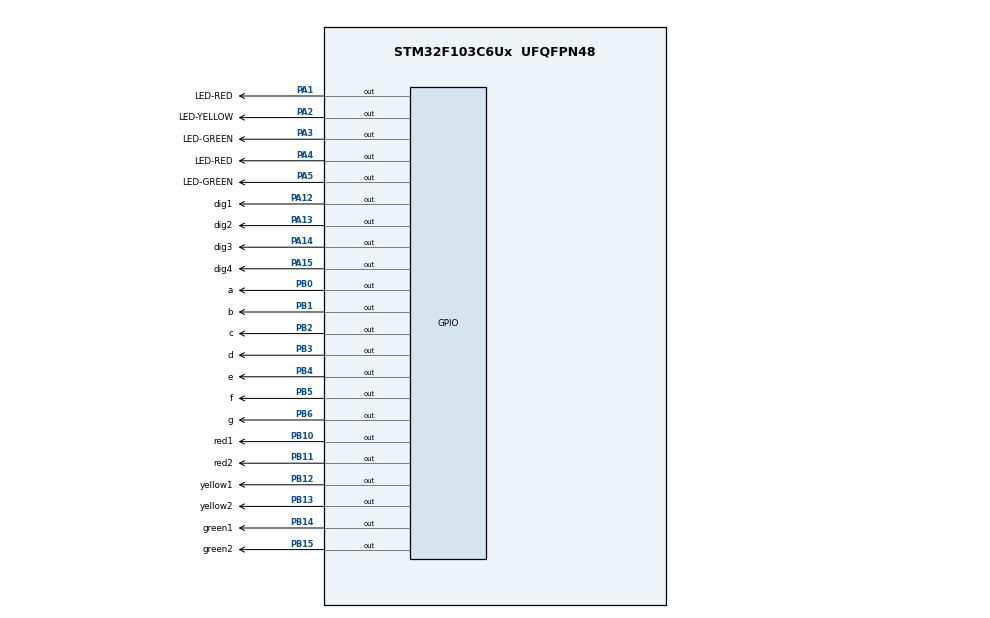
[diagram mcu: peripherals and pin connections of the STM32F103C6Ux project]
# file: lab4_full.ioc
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Mcu.Family=STM32F1
Mcu.Name=STM32F103C6Ux
Mcu.Package=UFQFPN48
NVIC.PriorityGroup=NVIC_PRIORITYGROUP_4
NVIC.TIM2_IRQn=true\:0\:0\:false\:false\:true\:true\:true
PA1.GPIO_Label=LED-RED
PA1.Signal=GPIO_Output
PA12.GPIO_Label=dig1
PA12.Signal=GPIO_Output
PA13.GPIO_Label=dig2
PA13.Signal=GPIO_Output
PA14.GPIO_Label=dig3
PA14.Signal=GPIO_Output
PA15.GPIO_Label=dig4
PA15.Signal=GPIO_Output
PA2.GPIO_Label=LED-YELLOW
PA2.Signal=GPIO_Output
PA3.GPIO_Label=LED-GREEN
PA3.Signal=GPIO_Output
PA4.GPIO_Label=LED-RED
PA4.Signal=GPIO_Output
PA5.GPIO_Label=LED-GREEN
PA5.Signal=GPIO_Output
PB0.GPIO_Label=a
PB0.Signal=GPIO_Output
PB1.GPIO_Label=b
PB1.Signal=GPIO_Output
PB10.GPIO_Label=red1
PB10.Signal=GPIO_Output
PB11.GPIO_Label=red2
PB11.Signal=GPIO_Output
PB12.GPIO_Label=yellow1
PB12.Signal=GPIO_Output
PB13.GPIO_Label=yellow2
PB13.Signal=GPIO_Output
PB14.GPIO_Label=green1
PB14.Signal=GPIO_Output
PB15.GPIO_Label=green2
PB15.Signal=GPIO_Output
PB2.GPIO_Label=c
PB2.Signal=GPIO_Output
PB3.GPIO_Label=d
PB3.Signal=GPIO_Output
PB4.GPIO_Label=e
PB4.Signal=GPIO_Output
PB5.GPIO_Label=f
PB5.Signal=GPIO_Output
PB6.GPIO_Label=g
PB6.Signal=GPIO_Output
ProjectManager.HeapSize=0x200
ProjectManager.StackSize=0x400
ProjectManager.TargetToolchain=STM32CubeIDE
RCC.APB1Freq_Value=8000000
RCC.APB2Freq_Value=8000000
TIM2.Period=9
TIM2.Prescaler=7999
VP_SYS_VS_ND.Mode=No_Debug
VP_TIM2_VS_ClockSourceINT.Mode=Internal
board=custom

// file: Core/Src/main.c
/* USER CODE BEGIN Header */
/**
  ******************************************************************************
  * @file           : main.c
  * @brief          : Main program body
  ******************************************************************************
  * @attention
  *
  * <h2><center>&copy; Copyright (c) 2024 STMicroelectronics.
  * All rights reserved.</center></h2>
  *
  * This software component is licensed by ST under BSD 3-Clause license,
  * the "License"; You may not use this file except in compliance with the
  * License. You may obtain a copy of the License at:
  * opensource.org/licenses/BSD-3-Clause
  *
  ******************************************************************************
  */
/* USER CODE END Header */
#include "main.h"

/* USER CODE BEGIN Includes */
#include "sched.h"
#include "func.h"
/* USER CODE END Includes */

TIM_HandleTypeDef htim2;

void SystemClock_Config(void);
static void MX_GPIO_Init(void);
static void MX_TIM2_Init(void);

int main(void)
{

  /* MCU Configuration--------------------------------------------------------*/

  /* Reset of all peripherals, Initializes the Flash interface and the Systick. */
  HAL_Init();

  /* Configure the system clock */
  SystemClock_Config();

  /* Initialize all configured peripherals */
  MX_GPIO_Init();
  MX_TIM2_Init();
  /* USER CODE BEGIN 2 */
  HAL_TIM_Base_Start_IT(&htim2);

  SCH_Init();

  // Yêu cầu 5 tasks: 0.5s, 1s, 1.5s, 2s, 2.5s
  // Timer tick của bạn là 10ms (từ MX_TIM2_Init, Prescaler 7999, Period 9)
  // 0.5s = 500ms  = 50 ticks
  // 1.0s = 1000ms = 100 ticks
  // 1.5s = 1500ms = 150 ticks
  // 2.0s = 2000ms = 200 ticks
  // 2.5s = 2500ms = 250 ticks

  SCH_Add_Task(turnREDLED, 10, 50, -1);     // Chạy mỗi 0.5s
  SCH_Add_Task(turnGREENLED, 10, 100, -1);  // Chạy mỗi 1.0s
  SCH_Add_Task(turnYELLOWLED, 10, 150, -1); // Chạy mỗi 1.5s
  SCH_Add_Task(turnRED, 10, 200, -1);       // Chạy mỗi 2.0s
  SCH_Add_Task(turnGreen, 10, 250, -1);     // Chạy mỗi 2.5s

  /* USER CODE END 2 */

  /* Infinite loop */
  /* USER CODE BEGIN WHILE */
  while (1)
  {
      SCH_Dispatch_Tasks(); // Yêu cầu của đề bài [cite: 679]
    /* USER CODE END WHILE */

  }
}

void SystemClock_Config(void)
{
  RCC_OscInitTypeDef RCC_OscInitStruct = {0};
  RCC_ClkInitTypeDef RCC_ClkInitStruct = {0};

  /** Initializes the RCC Oscillators according to the specified parameters
  * in the RCC_OscInitTypeDef structure.
  */
  RCC_OscInitStruct.OscillatorType = RCC_OSCILLATORTYPE_HSI;
  RCC_OscInitStruct.HSIState = RCC_HSI_ON;
  RCC_OscInitStruct.HSICalibrationValue = RCC_HSICALIBRATION_DEFAULT;
  RCC_OscInitStruct.PLL.PLLState = RCC_PLL_NONE;
  if (HAL_RCC_OscConfig(&RCC_OscInitStruct) != HAL_OK)
  {
    Error_Handler();
  }
  /** Initializes the CPU, AHB and APB buses clocks
  */
  RCC_ClkInitStruct.ClockType = RCC_CLOCKTYPE_HCLK|RCC_CLOCKTYPE_SYSCLK
                              |RCC_CLOCKTYPE_PCLK1|RCC_CLOCKTYPE_PCLK2;
  RCC_ClkInitStruct.SYSCLKSource = RCC_SYSCLKSOURCE_HSI;
  RCC_ClkInitStruct.AHBCLKDivider = RCC_SYSCLK_DIV1;
  RCC_ClkInitStruct.APB1CLKDivider = RCC_HCLK_DIV1;
  RCC_ClkInitStruct.APB2CLKDivider = RCC_HCLK_DIV1;

  if (HAL_RCC_ClockConfig(&RCC_ClkInitStruct, FLASH_LATENCY_0) != HAL_OK)
  {
    Error_Handler();
  }
}

static void MX_TIM2_Init(void)
{

  TIM_ClockConfigTypeDef sClockSourceConfig = {0};
  TIM_MasterConfigTypeDef sMasterConfig = {0};

  htim2.Instance = TIM2;
  htim2.Init.Prescaler = 7999;
  htim2.Init.CounterMode = TIM_COUNTERMODE_UP;
  htim2.Init.Period = 9;
  htim2.Init.ClockDivision = TIM_CLOCKDIVISION_DIV1;
  htim2.Init.AutoReloadPreload = TIM_AUTORELOAD_PRELOAD_DISABLE;
  if (HAL_TIM_Base_Init(&htim2) != HAL_OK)
  {
    Error_Handler();
  }
  sClockSourceConfig.ClockSource = TIM_CLOCKSOURCE_INTERNAL;
  if (HAL_TIM_ConfigClockSource(&htim2, &sClockSourceConfig) != HAL_OK)
  {
    Error_Handler();
  }
  sMasterConfig.MasterOutputTrigger = TIM_TRGO_RESET;
  sMasterConfig.MasterSlaveMode = TIM_MASTERSLAVEMODE_DISABLE;
  if (HAL_TIMEx_MasterConfigSynchronization(&htim2, &sMasterConfig) != HAL_OK)
  {
    Error_Handler();
  }

}

static void MX_GPIO_Init(void)
{
  GPIO_InitTypeDef GPIO_InitStruct = {0};

  /* GPIO Ports Clock Enable */
  __HAL_RCC_GPIOA_CLK_ENABLE();
  __HAL_RCC_GPIOB_CLK_ENABLE();

  /*Configure GPIO pin Output Level */
  HAL_GPIO_WritePin(GPIOA, LED_RED_Pin|LED_YELLOW_Pin|LED_GREEN_Pin|LED_REDA4_Pin
                          |LED_GREENA5_Pin|dig1_Pin|dig2_Pin|dig3_Pin
                          |dig4_Pin, GPIO_PIN_SET);

  /*Configure GPIO pin Output Level */
  HAL_GPIO_WritePin(GPIOB, a_Pin|b_Pin|c_Pin|red1_Pin
                          |red2_Pin|yellow1_Pin|yellow2_Pin|green1_Pin
                          |green2_Pin|d_Pin|e_Pin|f_Pin
                          |g_Pin, GPIO_PIN_SET);

  /*Configure GPIO pins : LED_RED_Pin LED_YELLOW_Pin LED_GREEN_Pin LED_REDA4_Pin
                           LED_GREENA5_Pin dig1_Pin dig2_Pin dig3_Pin
                           dig4_Pin */
  GPIO_InitStruct.Pin = LED_RED_Pin|LED_YELLOW_Pin|LED_GREEN_Pin|LED_REDA4_Pin
                          |LED_GREENA5_Pin|dig1_Pin|dig2_Pin|dig3_Pin
                          |dig4_Pin;
  GPIO_InitStruct.Mode = GPIO_MODE_OUTPUT_PP;
  GPIO_InitStruct.Pull = GPIO_NOPULL;
  GPIO_InitStruct.Speed = GPIO_SPEED_FREQ_LOW;
  HAL_GPIO_Init(GPIOA, &GPIO_InitStruct);

  /*Configure GPIO pins : a_Pin b_Pin c_Pin red1_Pin
                           red2_Pin yellow1_Pin yellow2_Pin green1_Pin
                           green2_Pin d_Pin e_Pin f_Pin
                           g_Pin */
  GPIO_InitStruct.Pin = a_Pin|b_Pin|c_Pin|red1_Pin
                          |red2_Pin|yellow1_Pin|yellow2_Pin|green1_Pin
                          |green2_Pin|d_Pin|e_Pin|f_Pin
                          |g_Pin;
  GPIO_InitStruct.Mode = GPIO_MODE_OUTPUT_PP;
  GPIO_InitStruct.Pull = GPIO_NOPULL;
  GPIO_InitStruct.Speed = GPIO_SPEED_FREQ_LOW;
  HAL_GPIO_Init(GPIOB, &GPIO_InitStruct);

}

/* USER CODE BEGIN 4 */
void HAL_TIM_PeriodElapsedCallback(TIM_HandleTypeDef *htim)
{
  if (htim->Instance == TIM2) {
      SCH_Update(); // Yêu cầu của đề bài [cite: 678]
  }
}
/* USER CODE END 4 */

void Error_Handler(void)
{
  __disable_irq();
  while (1)
  {
  }
}

/************************ (C) COPYRIGHT STMicroelectronics *****END OF FILE****/
